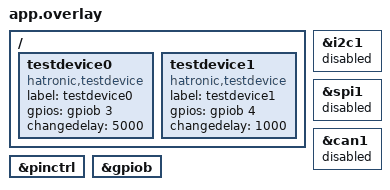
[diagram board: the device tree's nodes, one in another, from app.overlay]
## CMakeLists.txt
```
# Find Zephyr. This also loads Zephyr's build system.
cmake_minimum_required(VERSION 3.13.1)

set(CMAKE_EXPORT_COMPILE_COMMANDS 1)

# Temporarly select nucleo board
set(BOARD nucleo_l432kc)

# set(ZEPHYR_MODULES "~/dev/projects/zephyr_module_test")

find_package(Zephyr)
project(zephyr_playground)

# Add your source file to the "app" target. This must come after
# find_package(Zephyr) which defines the target.
target_sources(app PRIVATE src/main.c)

add_subdirectory(drivers)
```

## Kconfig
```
menu "Zephyr"
source "Kconfig.zephyr"
endmenu

rsource "drivers/Kconfig"
```

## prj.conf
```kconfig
CONFIG_GPIO=y
CONFIG_TEST_DEVICE=y
```

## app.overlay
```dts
/ {
    testdevice0: testdevice0 {
      compatible = "hatronic,testdevice";
      label = "testdevice0";
      gpios = <&gpiob 3 0>;
      status = "okay";
      changedelay = <5000>;
    };
    testdevice1: testdevice1 {
      compatible = "hatronic,testdevice";
      label = "testdevice1";
      gpios = <&gpiob 4 0>;
      status = "okay";
      changedelay = <1000>;
    };    
};

&i2c1 {
    status ="disabled";
};

&spi1{
    status ="disabled";
};

&can1 {
     status ="disabled";
};

&pinctrl {
  status = "okay";
};

&gpiob {
 status = "okay"; 
};
```

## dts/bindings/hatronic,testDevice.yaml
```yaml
description: |
  A test device used to test custom dts devices in zephyr.

  Example Definition:
    testdevice{
      compatible: "hatronic,testdevice";
      label: "Test Device";
      gpio: <&gpiob 10>;
    };

compatible: "hatronic,testdevice"

include: base.yaml

properties:
  gpios:
    type: phandle-array
    required: true
    description: The GPIO to use within the device
  changedelay: 
    type: int
    required: false
    default: 1000
    description: The amount of time in ms to wait before changing state
```

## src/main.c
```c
/**
 * @file main.c
 * @author Jeff Hatton
 * @brief Implementation for main
 * @date 2022-03-06
 * 
 * @copyright Copyright (c) 2022
 * 
 */

 #include <testDevice.h>

#include <device.h>

#include <logging/log.h>
LOG_MODULE_REGISTER(main, CONFIG_APP_LOG_LEVEL);

// Private Types ****************************************

// Constants ********************************************

// Macros ***********************************************

// Functions Prototypes *********************************

// Private Variables ************************************

#define NUM_SENSORS 2

// Private Functions *************************************

// Public Functions *************************************

void main()
{
    const struct device* dev0 = DEVICE_DT_GET(DT_NODELABEL(testdevice0));
    printk("Setting up devices\n");
	// if (!device_is_ready(dev0)) {
	// 	LOG_ERR("Device %u not ready", 0);
	// 	return;
	// }

    // // #if NUM_SENSORS >= 2

    // testDevices[1] = DEVICE_DT_GET(DT_NODELABEL(testdevice1));
	// if (!device_is_ready(testDevices[1])) {
	// 	LOG_ERR("Device %u not ready", 1);
	// 	return;
	// }

    // // #endif

    while (1)
    {
        for (uint16_t i = 0; i < NUM_SENSORS; i++)
        {
            TestDevice_Update(dev0);
        }
        
        k_sleep(K_MSEC(1));
    }

    return;
}
```
